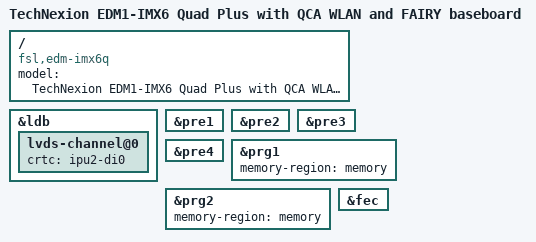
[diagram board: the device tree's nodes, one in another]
/*
 * Copyright 2016 Technexion Ltd.
 *
 * Author: Tapani Utriainen <tapani@technexion.com>
 *         Richard Hu <richard.hu@technexion.com>
 *
 * The code contained herein is licensed under the GNU General Public
 * License. You may obtain a copy of the GNU General Public License
 * Version 2 or later at the following locations:
 *
 * http://www.opensource.org/licenses/gpl-license.html
 * http://www.gnu.org/copyleft/gpl.html
 */

/dts-v1/;
#include <dt-bindings/interrupt-controller/irq.h>
#include "imx6qp.dtsi"
#include "imx6qdl-edm-qca.dtsi"
#include "baseboard_edm1_gnome.dtsi"

/ {
	model = "TechNexion EDM1-IMX6 Quad Plus with QCA WLAN and FAIRY baseboard";
	compatible = "fsl,edm-imx6q", "fsl,imx6q";
};

&ldb {
	lvds-channel@0 {
		crtc = "ipu2-di0";
	};
};

&pre1 {
	status = "okay";
};

&pre2 {
	status = "okay";
};

&pre3 {
	status = "okay";
};

&pre4 {
	status = "okay";
};

&prg1 {
	memory-region = <&memory>;
	status = "okay";
};

&prg2 {
	memory-region = <&memory>;
	status = "okay";
};

&fec {
    /delete-property/ phy-reset-gpios;
};
